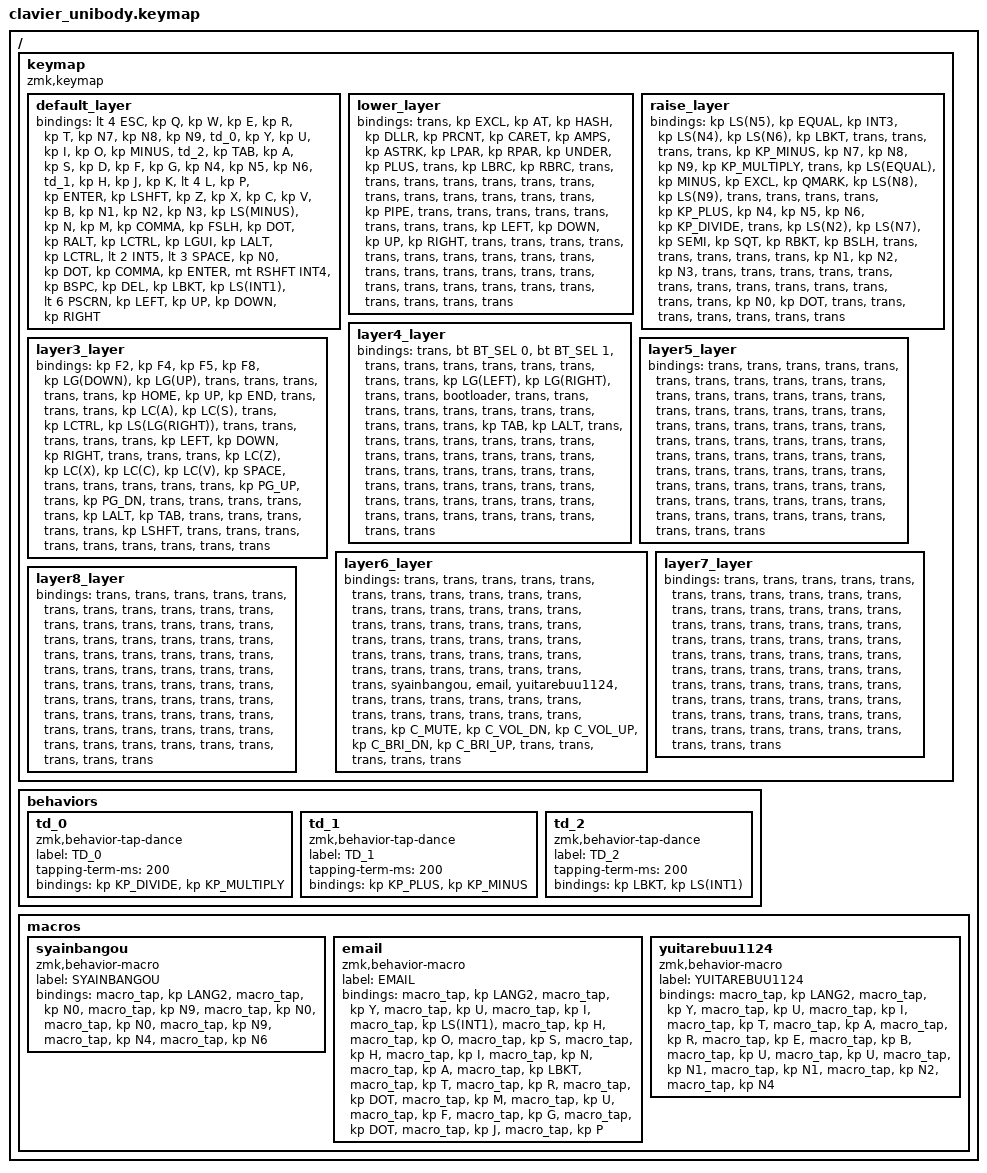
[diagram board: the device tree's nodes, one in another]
/*
 * ZMK Keymap - Generated by ZMK Keymap Editor
 * Do not edit manually unless you know what you're doing.
 */

#include <behaviors.dtsi>
#include <dt-bindings/zmk/bt.h>
#include <dt-bindings/zmk/keys.h>
#include <dt-bindings/zmk/outputs.h>
#include <dt-bindings/zmk/mouse.h>

#define DEFAULT 0
#define LAYER1 1
#define LAYER2 2
#define LAYER3 3
#define LAYER4 4
#define LAYER_5 5
#define LAYER_6 6
#define LAYER_7 7
#define LAYER_8 8

/ {
    keymap {
        compatible = "zmk,keymap";

        default_layer {
            bindings = <
                &lt 4 ESC  &kp Q  &kp W  &kp E  &kp R  &kp T  &kp N7  &kp N8  &kp N9  &td_0  &kp Y  &kp U  &kp I  &kp O  &kp MINUS  &td_2  &kp TAB  &kp A  &kp S  &kp D  &kp F  &kp G  &kp N4  &kp N5  &kp N6  &td_1  &kp H  &kp J  &kp K  &lt 4 L  &kp P  &kp ENTER  &kp LSHFT  &kp Z  &kp X  &kp C  &kp V  &kp B  &kp N1  &kp N2  &kp N3  &kp LS(MINUS)  &kp N  &kp M  &kp COMMA  &kp FSLH  &kp DOT  &kp RALT  &kp LCTRL  &kp LGUI  &kp LALT  &kp LCTRL  &lt 2 INT5  &lt 3 SPACE  &kp N0  &kp DOT  &kp COMMA  &kp ENTER  &mt RSHFT INT4  &kp BSPC  &kp DEL  &kp LBKT  &kp LS(INT1)  &lt 6 PSCRN  &kp LEFT  &kp UP  &kp DOWN  &kp RIGHT
            >;
        };

        lower_layer {
            bindings = <
                &trans  &kp EXCL  &kp AT  &kp HASH  &kp DLLR  &kp PRCNT  &kp CARET  &kp AMPS  &kp ASTRK  &kp LPAR  &kp RPAR  &kp UNDER  &kp PLUS  &trans  &kp LBRC  &kp RBRC  &trans  &trans  &trans  &trans  &trans  &trans  &trans  &trans  &trans  &trans  &trans  &trans  &trans  &kp PIPE  &trans  &trans  &trans  &trans  &trans  &trans  &trans  &trans  &kp LEFT  &kp DOWN  &kp UP  &kp RIGHT  &trans  &trans  &trans  &trans  &trans  &trans  &trans  &trans  &trans  &trans  &trans  &trans  &trans  &trans  &trans  &trans  &trans  &trans  &trans  &trans  &trans  &trans  &trans  &trans  &trans  &trans
            >;
        };

        raise_layer {
            bindings = <
                &kp LS(N5)  &kp EQUAL  &kp INT3  &kp LS(N4)  &kp LS(N6)  &kp LBKT  &trans  &trans  &trans  &trans  &kp KP_MINUS  &kp N7  &kp N8  &kp N9  &kp KP_MULTIPLY  &trans  &kp LS(EQUAL)  &kp MINUS  &kp EXCL  &kp QMARK  &kp LS(N8)  &kp LS(N9)  &trans  &trans  &trans  &trans  &kp KP_PLUS  &kp N4  &kp N5  &kp N6  &kp KP_DIVIDE  &trans  &kp LS(N2)  &kp LS(N7)  &kp SEMI  &kp SQT  &kp RBKT  &kp BSLH  &trans  &trans  &trans  &trans  &trans  &kp N1  &kp N2  &kp N3  &trans  &trans  &trans  &trans  &trans  &trans  &trans  &trans  &trans  &trans  &trans  &trans  &trans  &kp N0  &kp DOT  &trans  &trans  &trans  &trans  &trans  &trans  &trans
            >;
        };

        layer3_layer {
            bindings = <
                &kp F2  &kp F4  &kp F5  &kp F8  &kp LG(DOWN)  &kp LG(UP)  &trans  &trans  &trans  &trans  &trans  &kp HOME  &kp UP  &kp END  &trans  &trans  &trans  &kp LC(A)  &kp LC(S)  &trans  &kp LCTRL  &kp LS(LG(RIGHT))  &trans  &trans  &trans  &trans  &trans  &kp LEFT  &kp DOWN  &kp RIGHT  &trans  &trans  &trans  &kp LC(Z)  &kp LC(X)  &kp LC(C)  &kp LC(V)  &kp SPACE  &trans  &trans  &trans  &trans  &trans  &kp PG_UP  &trans  &kp PG_DN  &trans  &trans  &trans  &trans  &trans  &kp LALT  &kp TAB  &trans  &trans  &trans  &trans  &trans  &kp LSHFT  &trans  &trans  &trans  &trans  &trans  &trans  &trans  &trans  &trans
            >;
        };

        layer4_layer {
            bindings = <
                &trans  &bt BT_SEL 0  &bt BT_SEL 1  &trans  &trans  &trans  &trans  &trans  &trans  &trans  &trans  &kp LG(LEFT)  &kp LG(RIGHT)  &trans  &trans  &bootloader  &trans  &trans  &trans  &trans  &trans  &trans  &trans  &trans  &trans  &trans  &trans  &kp TAB  &kp LALT  &trans  &trans  &trans  &trans  &trans  &trans  &trans  &trans  &trans  &trans  &trans  &trans  &trans  &trans  &trans  &trans  &trans  &trans  &trans  &trans  &trans  &trans  &trans  &trans  &trans  &trans  &trans  &trans  &trans  &trans  &trans  &trans  &trans  &trans  &trans  &trans  &trans  &trans  &trans
            >;
        };

        layer5_layer {
            bindings = <
                &trans  &trans  &trans  &trans  &trans  &trans  &trans  &trans  &trans  &trans  &trans  &trans  &trans  &trans  &trans  &trans  &trans  &trans  &trans  &trans  &trans  &trans  &trans  &trans  &trans  &trans  &trans  &trans  &trans  &trans  &trans  &trans  &trans  &trans  &trans  &trans  &trans  &trans  &trans  &trans  &trans  &trans  &trans  &trans  &trans  &trans  &trans  &trans  &trans  &trans  &trans  &trans  &trans  &trans  &trans  &trans  &trans  &trans  &trans  &trans  &trans  &trans  &trans  &trans  &trans  &trans  &trans  &trans
            >;
        };

        layer6_layer {
            bindings = <
                &trans  &trans  &trans  &trans  &trans  &trans  &trans  &trans  &trans  &trans  &trans  &trans  &trans  &trans  &trans  &trans  &trans  &trans  &trans  &trans  &trans  &trans  &trans  &trans  &trans  &trans  &trans  &trans  &trans  &trans  &trans  &trans  &trans  &trans  &trans  &trans  &trans  &trans  &trans  &trans  &trans  &trans  &syainbangou  &email  &yuitarebuu1124  &trans  &trans  &trans  &trans  &trans  &trans  &trans  &trans  &trans  &trans  &trans  &trans  &trans  &kp C_MUTE  &kp C_VOL_DN  &kp C_VOL_UP  &kp C_BRI_DN  &kp C_BRI_UP  &trans  &trans  &trans  &trans  &trans
            >;
        };

        layer7_layer {
            bindings = <
                &trans  &trans  &trans  &trans  &trans  &trans  &trans  &trans  &trans  &trans  &trans  &trans  &trans  &trans  &trans  &trans  &trans  &trans  &trans  &trans  &trans  &trans  &trans  &trans  &trans  &trans  &trans  &trans  &trans  &trans  &trans  &trans  &trans  &trans  &trans  &trans  &trans  &trans  &trans  &trans  &trans  &trans  &trans  &trans  &trans  &trans  &trans  &trans  &trans  &trans  &trans  &trans  &trans  &trans  &trans  &trans  &trans  &trans  &trans  &trans  &trans  &trans  &trans  &trans  &trans  &trans  &trans  &trans
            >;
        };

        layer8_layer {
            bindings = <
                &trans  &trans  &trans  &trans  &trans  &trans  &trans  &trans  &trans  &trans  &trans  &trans  &trans  &trans  &trans  &trans  &trans  &trans  &trans  &trans  &trans  &trans  &trans  &trans  &trans  &trans  &trans  &trans  &trans  &trans  &trans  &trans  &trans  &trans  &trans  &trans  &trans  &trans  &trans  &trans  &trans  &trans  &trans  &trans  &trans  &trans  &trans  &trans  &trans  &trans  &trans  &trans  &trans  &trans  &trans  &trans  &trans  &trans  &trans  &trans  &trans  &trans  &trans  &trans  &trans  &trans  &trans  &trans
            >;
        };
    };

    behaviors {
        td_0: td_0 {
            compatible = "zmk,behavior-tap-dance";
            label = "TD_0";
            #binding-cells = <0>;
            tapping-term-ms = <200>;
            bindings = <&kp KP_DIVIDE>, <&kp KP_MULTIPLY>;
        };
        td_1: td_1 {
            compatible = "zmk,behavior-tap-dance";
            label = "TD_1";
            #binding-cells = <0>;
            tapping-term-ms = <200>;
            bindings = <&kp KP_PLUS>, <&kp KP_MINUS>;
        };
        td_2: td_2 {
            compatible = "zmk,behavior-tap-dance";
            label = "TD_2";
            #binding-cells = <0>;
            tapping-term-ms = <200>;
            bindings = <&kp LBKT>, <&kp LS(INT1)>;
        };
    };
    macros {
        syainbangou: syainbangou {
            compatible = "zmk,behavior-macro";
            label = "SYAINBANGOU";
            #binding-cells = <0>;
            bindings = <
                &macro_tap &kp LANG2
                &macro_tap &kp N0
                &macro_tap &kp N9
                &macro_tap &kp N0
                &macro_tap &kp N0
                &macro_tap &kp N9
                &macro_tap &kp N4
                &macro_tap &kp N6
            >;
        };
        email: email {
            compatible = "zmk,behavior-macro";
            label = "EMAIL";
            #binding-cells = <0>;
            bindings = <
                &macro_tap &kp LANG2
                &macro_tap &kp Y
                &macro_tap &kp U
                &macro_tap &kp I
                &macro_tap &kp LS(INT1)
                &macro_tap &kp H
                &macro_tap &kp O
                &macro_tap &kp S
                &macro_tap &kp H
                &macro_tap &kp I
                &macro_tap &kp N
                &macro_tap &kp A
                &macro_tap &kp LBKT
                &macro_tap &kp T
                &macro_tap &kp R
                &macro_tap &kp DOT
                &macro_tap &kp M
                &macro_tap &kp U
                &macro_tap &kp F
                &macro_tap &kp G
                &macro_tap &kp DOT
                &macro_tap &kp J
                &macro_tap &kp P
            >;
        };
        yuitarebuu1124: yuitarebuu1124 {
            compatible = "zmk,behavior-macro";
            label = "YUITAREBUU1124";
            #binding-cells = <0>;
            bindings = <
                &macro_tap &kp LANG2
                &macro_tap &kp Y
                &macro_tap &kp U
                &macro_tap &kp I
                &macro_tap &kp T
                &macro_tap &kp A
                &macro_tap &kp R
                &macro_tap &kp E
                &macro_tap &kp B
                &macro_tap &kp U
                &macro_tap &kp U
                &macro_tap &kp N1
                &macro_tap &kp N1
                &macro_tap &kp N2
                &macro_tap &kp N4
            >;
        };
    };
};
